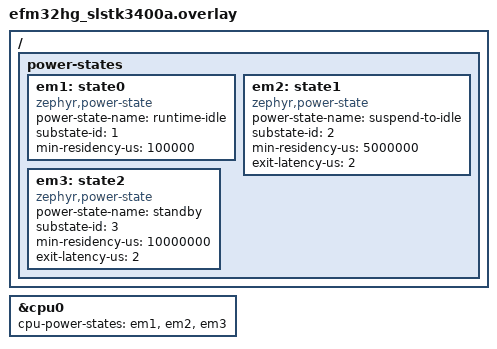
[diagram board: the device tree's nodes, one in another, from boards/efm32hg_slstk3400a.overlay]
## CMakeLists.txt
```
cmake_minimum_required(VERSION 3.13.1)

set(SelectedBoard efm32hg_slstk3400a)

set(BOARD ${SelectedBoard})
set(DTC_OVERLAY_FILE ./boards/${SelectedBoard}.overlay)

include($ENV{ZEPHYR_BASE}/cmake/app/boilerplate.cmake NO_POLICY_SCOPE)
project(efm32sleep_test)

FILE(GLOB app_sources ./src/*.c*)

target_sources(app PRIVATE ${app_sources} ${lib_sources})
```

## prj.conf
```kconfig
#CONFIG_CMU_HFRCO_FREQ=1200000
#CONFIG_SYS_CLOCK_HW_CYCLES_PER_SEC=1200000

CONFIG_PM=y
CONFIG_PM_DEVICE=y
CONFIG_PM_DEVICE_RUNTIME=y
CONFIG_PM_STATS=y


CONFIG_LOG=y
CONFIG_LOG_DEFAULT_LEVEL=4
CONFIG_LOG_MODE_MINIMAL=y
CONFIG_SOC_LOG_LEVEL_DBG=y
CONFIG_PM_LOG_LEVEL_DBG=y
```

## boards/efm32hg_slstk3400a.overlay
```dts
/ {
	power-states {
		em1: state0 {
			compatible = "zephyr,power-state";
			power-state-name = "runtime-idle";
			substate-id = <1>;
			min-residency-us = <100000>;
		};
		em2: state1 {
			compatible = "zephyr,power-state";
			power-state-name = "suspend-to-idle";
			substate-id = <2>;
			min-residency-us = <5000000>;
			exit-latency-us = <2>;
		};
		em3: state2 {
			compatible = "zephyr,power-state";
			power-state-name = "standby";
			substate-id = <3>;
			min-residency-us = <10000000>;
			exit-latency-us = <2>;
		};

	};
};

&cpu0 {
	//clock-frequency = <1200000>;
	cpu-power-states = <&em1 &em2 &em3>;
};
```

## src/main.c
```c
#include <zephyr.h>
#include <logging/log.h>
#include <stdio.h>

LOG_MODULE_REGISTER(main, CONFIG_LOG_DEFAULT_LEVEL);


void main(void)
{   int i=0;
    LOG_INF("HELLO");
    while(true) {
        printf("ROUND %d\n", i);
        i++;
        k_msleep(1000);
    }
}
```
